# MKW36Z4 register map
Vendor: NXP Semiconductors; Series: Kinetis_W; File version: 1.6
CPU: CM0PLUS r0p0, little endian, no MPU, no FPU, VTOR, 2 interrupt priority bits
Registers are 16-bit, read-write, no defined reset value unless marked. A register's access mark holds for its fields unless they carry their own. Offsets are from the block's base; [hi:lo] are bit positions; {n}, {i} and the like mark numbered series; 'fields as' and 'values as' point back to an identical list.

## XCVR_TSM
Base 0x4005C2C0
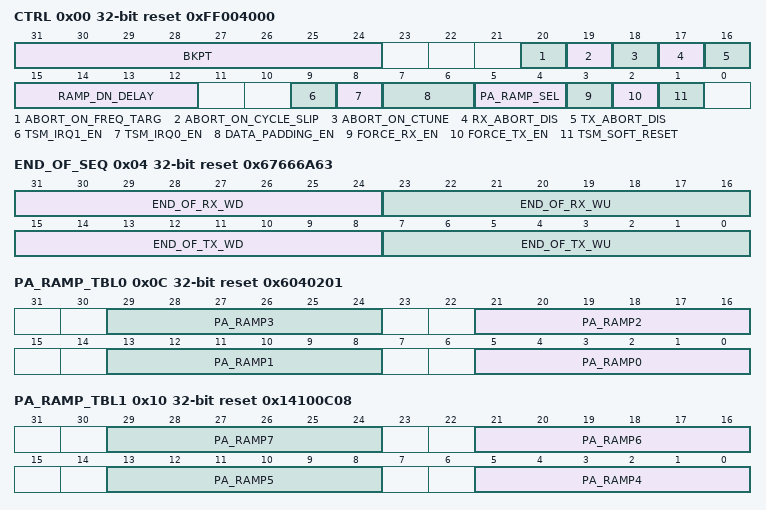
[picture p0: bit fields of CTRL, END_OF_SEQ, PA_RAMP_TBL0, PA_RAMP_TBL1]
0x00 CTRL 32-bit reset 0xFF004000 — TSM CONTROL
  [31:24] BKPT — TSM Breakpoint
  [20] ABORT_ON_FREQ_TARG — Abort On Frequency Target Lock Detect Failure
    0=don't allow TSM abort on Frequency Target Unlock Detect; 1=allow TSM abort on Frequency Target Unlock Detect
  [19] ABORT_ON_CYCLE_SLIP — Abort On Cycle Slip Lock Detect Failure
    0=don't allow TSM abort on Cycle Slip Unlock Detect; 1=allow TSM abort on Cycle Slip Unlock Detect
  [18] ABORT_ON_CTUNE — Abort On Coarse Tune Lock Detect Failure
    0=don't allow TSM abort on Coarse Tune Unlock Detect; 1=allow TSM abort on Coarse Tune Unlock Detect
  [17] RX_ABORT_DIS — Receive Abort Disable
  [16] TX_ABORT_DIS — Transmit Abort Disable
  [15:12] RAMP_DN_DELAY — PA Ramp Down Delay
  [9] TSM_IRQ1_EN — TSM_IRQ1 Enable/Disable bit
    0=TSM_IRQ1 is disabled; 1=TSM_IRQ1 is enabled
  [8] TSM_IRQ0_EN — TSM_IRQ0 Enable/Disable bit
    0=TSM_IRQ0 is disabled; 1=TSM_IRQ0 is enabled
  [7:6] DATA_PADDING_EN — Data Padding Enable
    0=Disable TX Data Padding; 1=Enable TX Data Padding
  [5:4] PA_RAMP_SEL — PA Ramp Selection
  [3] FORCE_RX_EN — Force Receive Enable
    0=TSM Idle; 1=TSM executes a RX sequence
  [2] FORCE_TX_EN — Force Transmit Enable
    0=TSM Idle; 1=TSM executes a TX sequence
  [1] TSM_SOFT_RESET
    0=TSM Soft Reset removed. Normal operation.; 1=TSM Soft Reset engaged. TSM forced to IDLE, and holds there until the bit is cleared.
0x04 END_OF_SEQ 32-bit reset 0x67666A63 — TSM END OF SEQUENCE
  [31:24] END_OF_RX_WD — End of RX Warmdown
  [23:16] END_OF_RX_WU — End of RX Warmup
  [15:8] END_OF_TX_WD — End of TX Warmdown
  [7:0] END_OF_TX_WU — End of TX Warmup
0x08 PA_POWER 32-bit reset 0x0
  [5:0] PA_POWER
0x0C PA_RAMP_TBL0 32-bit reset 0x6040201 — PA RAMP TABLE 0
  [8n+5:8n] PA_RAMP{n} (n=0..3)
0x10 PA_RAMP_TBL1 32-bit reset 0x14100C08 — PA RAMP TABLE 1
  [8n-27:8n-32] PA_RAMP{n} (n=4..7)
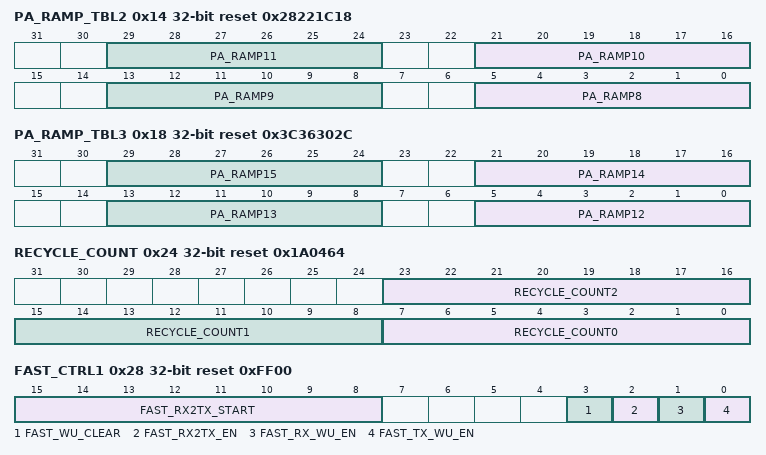
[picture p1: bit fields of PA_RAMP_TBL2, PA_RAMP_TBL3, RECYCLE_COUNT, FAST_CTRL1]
0x14 PA_RAMP_TBL2 32-bit reset 0x28221C18 — PA RAMP TABLE 2
  [8n-59:8n-64] PA_RAMP{n} (n=8..11)
0x18 PA_RAMP_TBL3 32-bit reset 0x3C36302C — PA RAMP TABLE 3
  [8n-91:8n-96] PA_RAMP{n} (n=12..15)
0x24 RECYCLE_COUNT 32-bit reset 0x1A0464 — TSM RECYCLE COUNT
  [23:16] RECYCLE_COUNT2 — TSM RX Recycle Count 2
  [15:8] RECYCLE_COUNT1 — TSM RX Recycle Count 1
  [7:0] RECYCLE_COUNT0 — TSM RX Recycle Count 0
0x28 FAST_CTRL1 32-bit reset 0xFF00 — TSM FAST WARMUP CONTROL 1
  [15:8] FAST_RX2TX_START — These bits currently have no functionality.
  [3] FAST_WU_CLEAR — Fast TSM Warmup Clear State
  [2] FAST_RX2TX_EN — Fast TSM RX-to-TX Transition Enable
  [1] FAST_RX_WU_EN — Fast TSM RX Warmup Enable
    0=Fast TSM RX Warmups are disabled; 1=Fast TSM RX Warmups are enabled, if the RF channel has not changed since the last RX warmup, and for BLE mode, the RF channel is not an advertising channel
  [0] FAST_TX_WU_EN — Fast TSM TX Warmup Enable
    0=Fast TSM TX Warmups are disabled; 1=Fast TSM TX Warmups are enabled, if the RF channel has not changed since the last TX warmup, and for BLE mode, the RF channel is not an advertising channel
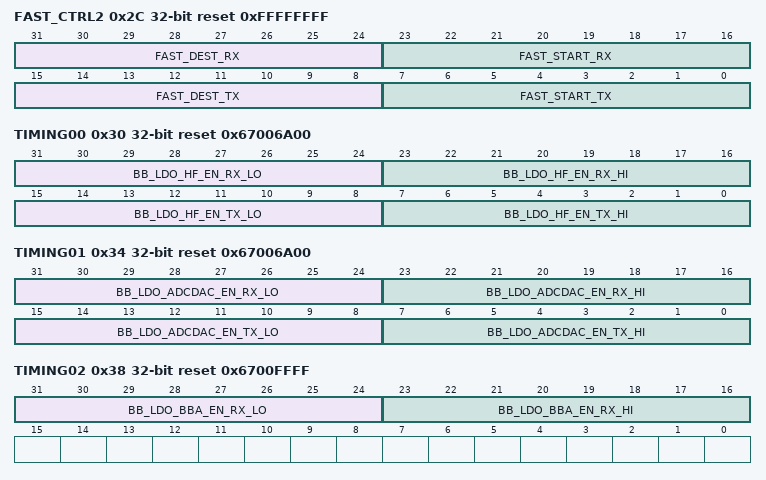
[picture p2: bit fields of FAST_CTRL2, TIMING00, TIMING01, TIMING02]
0x2C FAST_CTRL2 32-bit reset 0xFFFFFFFF — TSM FAST WARMUP CONTROL 2
  [31:24] FAST_DEST_RX — Fast TSM RX "Jump-to" Point
  [23:16] FAST_START_RX — Fast TSM RX "Jump-from" Point
  [15:8] FAST_DEST_TX — Fast TSM TX "Jump-to" Point
  [7:0] FAST_START_TX — Fast TSM TX "Jump-from" Point
0x30 TIMING00 32-bit reset 0x67006A00 — TSM_TIMING00
  [31:24] BB_LDO_HF_EN_RX_LO — De-assertion time setting for BB_LDO_HF_EN (RX)
  [23:16] BB_LDO_HF_EN_RX_HI — Assertion time setting for BB_LDO_HF_EN (RX)
  [15:8] BB_LDO_HF_EN_TX_LO — De-assertion time setting for BB_LDO_HF_EN (TX)
  [7:0] BB_LDO_HF_EN_TX_HI — Assertion time setting for BB_LDO_HF_EN (TX)
0x34 TIMING01 32-bit reset 0x67006A00 — TSM_TIMING01
  [31:24] BB_LDO_ADCDAC_EN_RX_LO — De-assertion time setting for BB_LDO_ADCDAC_EN (RX)
  [23:16] BB_LDO_ADCDAC_EN_RX_HI — Assertion time setting for BB_LDO_ADCDAC_EN (RX)
  [15:8] BB_LDO_ADCDAC_EN_TX_LO — De-assertion time setting for BB_LDO_ADCDAC_EN (TX)
  [7:0] BB_LDO_ADCDAC_EN_TX_HI — Assertion time setting for BB_LDO_ADCDAC_EN (TX)
0x38 TIMING02 32-bit reset 0x6700FFFF — TSM_TIMING02
  [31:24] BB_LDO_BBA_EN_RX_LO — De-assertion time setting for BB_LDO_BBA_EN (RX)
  [23:16] BB_LDO_BBA_EN_RX_HI — Assertion time setting for BB_LDO_BBA_EN (RX)
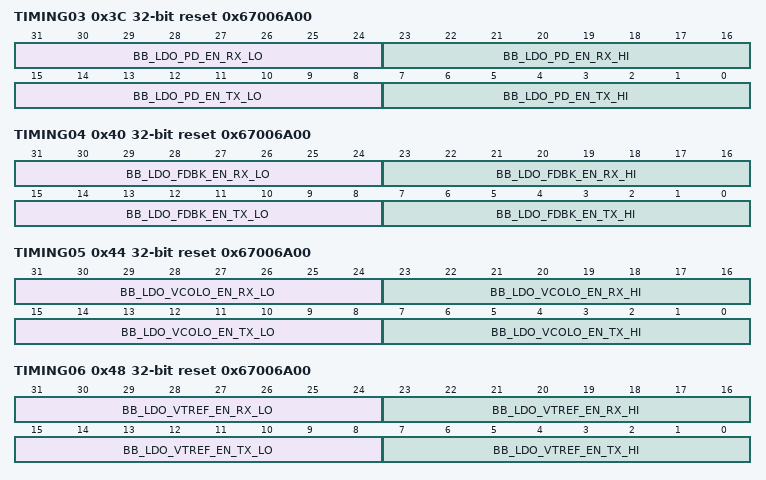
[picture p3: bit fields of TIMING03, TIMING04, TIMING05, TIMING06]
0x3C TIMING03 32-bit reset 0x67006A00 — TSM_TIMING03
  [31:24] BB_LDO_PD_EN_RX_LO — De-assertion time setting for BB_LDO_PD_EN (RX)
  [23:16] BB_LDO_PD_EN_RX_HI — Assertion time setting for BB_LDO_PD_EN (RX)
  [15:8] BB_LDO_PD_EN_TX_LO — De-assertion time setting for BB_LDO_PD_EN (TX)
  [7:0] BB_LDO_PD_EN_TX_HI — Assertion time setting for BB_LDO_PD_EN (TX)
0x40 TIMING04 32-bit reset 0x67006A00 — TSM_TIMING04
  [31:24] BB_LDO_FDBK_EN_RX_LO — De-assertion time setting for BB_LDO_FDBK_EN (RX)
  [23:16] BB_LDO_FDBK_EN_RX_HI — Assertion time setting for BB_LDO_FDBK_EN (RX)
  [15:8] BB_LDO_FDBK_EN_TX_LO — De-assertion time setting for BB_LDO_FDBK_EN (TX)
  [7:0] BB_LDO_FDBK_EN_TX_HI — Assertion time setting for BB_LDO_FDBK_EN (TX)
0x44 TIMING05 32-bit reset 0x67006A00 — TSM_TIMING05
  [31:24] BB_LDO_VCOLO_EN_RX_LO — De-assertion time setting for BB_LDO_VCOLO_EN (RX)
  [23:16] BB_LDO_VCOLO_EN_RX_HI — Assertion time setting for BB_LDO_VCOLO_EN (RX)
  [15:8] BB_LDO_VCOLO_EN_TX_LO — De-assertion time setting for BB_LDO_VCOLO_EN (TX)
  [7:0] BB_LDO_VCOLO_EN_TX_HI — Assertion time setting for BB_LDO_VCOLO_EN (TX)
0x48 TIMING06 32-bit reset 0x67006A00 — TSM_TIMING06
  [31:24] BB_LDO_VTREF_EN_RX_LO — De-assertion time setting for BB_LDO_VTREF_EN (RX)
  [23:16] BB_LDO_VTREF_EN_RX_HI — Assertion time setting for BB_LDO_VTREF_EN (RX)
  [15:8] BB_LDO_VTREF_EN_TX_LO — De-assertion time setting for BB_LDO_VTREF_EN (TX)
  [7:0] BB_LDO_VTREF_EN_TX_HI — Assertion time setting for BB_LDO_VTREF_EN (TX)
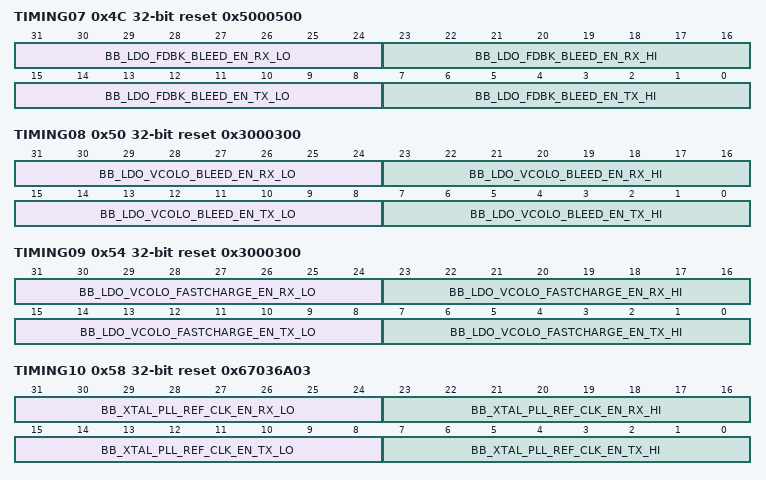
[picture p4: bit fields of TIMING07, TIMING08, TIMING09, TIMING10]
0x4C TIMING07 32-bit reset 0x5000500 — TSM_TIMING07
  [31:24] BB_LDO_FDBK_BLEED_EN_RX_LO — De-assertion time setting for BB_LDO_FDBK_BLEED_EN (RX)
  [23:16] BB_LDO_FDBK_BLEED_EN_RX_HI — Assertion time setting for BB_LDO_FDBK_BLEED_EN (RX)
  [15:8] BB_LDO_FDBK_BLEED_EN_TX_LO — De-assertion time setting for BB_LDO_FDBK_BLEED_EN (TX)
  [7:0] BB_LDO_FDBK_BLEED_EN_TX_HI — Assertion time setting for BB_LDO_FDBK_BLEED_EN (TX)
0x50 TIMING08 32-bit reset 0x3000300 — TSM_TIMING08
  [31:24] BB_LDO_VCOLO_BLEED_EN_RX_LO — De-assertion time setting for BB_LDO_VCOLO_BLEED_EN (RX)
  [23:16] BB_LDO_VCOLO_BLEED_EN_RX_HI — Assertion time setting for BB_LDO_VCOLO_BLEED_EN (RX)
  [15:8] BB_LDO_VCOLO_BLEED_EN_TX_LO — De-assertion time setting for BB_LDO_VCOLO_BLEED_EN (TX)
  [7:0] BB_LDO_VCOLO_BLEED_EN_TX_HI — Assertion time setting for BB_LDO_VCOLO_BLEED_EN (TX)
0x54 TIMING09 32-bit reset 0x3000300 — TSM_TIMING09
  [31:24] BB_LDO_VCOLO_FASTCHARGE_EN_RX_LO — De-assertion time setting for BB_LDO_VCOLO_FASTCHARGE_EN (RX)
  [23:16] BB_LDO_VCOLO_FASTCHARGE_EN_RX_HI — Assertion time setting for BB_LDO_VCOLO_FASTCHARGE_EN (RX)
  [15:8] BB_LDO_VCOLO_FASTCHARGE_EN_TX_LO — De-assertion time setting for BB_LDO_VCOLO_FASTCHARGE_EN (TX)
  [7:0] BB_LDO_VCOLO_FASTCHARGE_EN_TX_HI — Assertion time setting for BB_LDO_VCOLO_FASTCHARGE_EN (TX)
0x58 TIMING10 32-bit reset 0x67036A03 — TSM_TIMING10
  [31:24] BB_XTAL_PLL_REF_CLK_EN_RX_LO — De-assertion time setting for BB_XTAL_PLL_REF_CLK_EN (RX)
  [23:16] BB_XTAL_PLL_REF_CLK_EN_RX_HI — Assertion time setting for BB_XTAL_PLL_REF_CLK_EN (RX)
  [15:8] BB_XTAL_PLL_REF_CLK_EN_TX_LO — De-assertion time setting for BB_XTAL_PLL_REF_CLK_EN (TX)
  [7:0] BB_XTAL_PLL_REF_CLK_EN_TX_HI — Assertion time setting for BB_XTAL_PLL_REF_CLK_EN (TX)
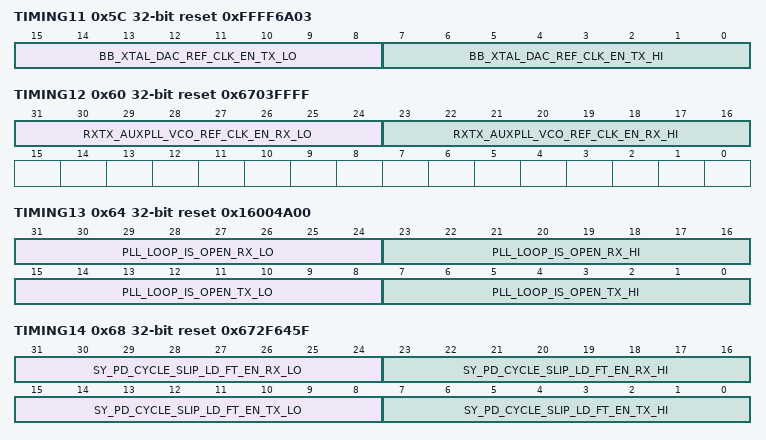
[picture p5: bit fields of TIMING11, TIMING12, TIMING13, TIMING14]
0x5C TIMING11 32-bit reset 0xFFFF6A03 — TSM_TIMING11
  [15:8] BB_XTAL_DAC_REF_CLK_EN_TX_LO — De-assertion time setting for BB_XTAL_DAC_REF_CLK_EN (TX)
  [7:0] BB_XTAL_DAC_REF_CLK_EN_TX_HI — Assertion time setting for BB_XTAL_DAC_REF_CLK_EN (TX)
0x60 TIMING12 32-bit reset 0x6703FFFF — TSM_TIMING12
  [31:24] RXTX_AUXPLL_VCO_REF_CLK_EN_RX_LO — De-assertion time setting for RXTX_AUXPLL_VCO_REF_CLK_EN (RX)
  [23:16] RXTX_AUXPLL_VCO_REF_CLK_EN_RX_HI — Assertion time setting for RXTX_AUXPLL_VCO_REF_CLK_EN (RX)
0x64 TIMING13 32-bit reset 0x16004A00 — TSM_TIMING13
  [31:24] PLL_LOOP_IS_OPEN_RX_LO — De-assertion time setting for PLL_LOOP_IS_OPEN (RX)
  [23:16] PLL_LOOP_IS_OPEN_RX_HI — Assertion time setting for PLL_LOOP_IS_OPEN (RX)
  [15:8] PLL_LOOP_IS_OPEN_TX_LO — De-assertion time setting for PLL_LOOP_IS_OPEN (TX)
  [7:0] PLL_LOOP_IS_OPEN_TX_HI — Assertion time setting for PLL_LOOP_IS_OPEN (TX)
0x68 TIMING14 32-bit reset 0x672F645F — TSM_TIMING14
  [31:24] SY_PD_CYCLE_SLIP_LD_FT_EN_RX_LO — De-assertion time setting for SY_PD_CYCLE_SLIP_LD_FT_EN (RX)
  [23:16] SY_PD_CYCLE_SLIP_LD_FT_EN_RX_HI — Assertion time setting for SY_PD_CYCLE_SLIP_LD_FT_EN (RX)
  [15:8] SY_PD_CYCLE_SLIP_LD_FT_EN_TX_LO — De-assertion time setting for SY_PD_CYCLE_SLIP_LD_FT_EN (TX)
  [7:0] SY_PD_CYCLE_SLIP_LD_FT_EN_TX_HI — Assertion time setting for SY_PD_CYCLE_SLIP_LD_FT_EN (TX)
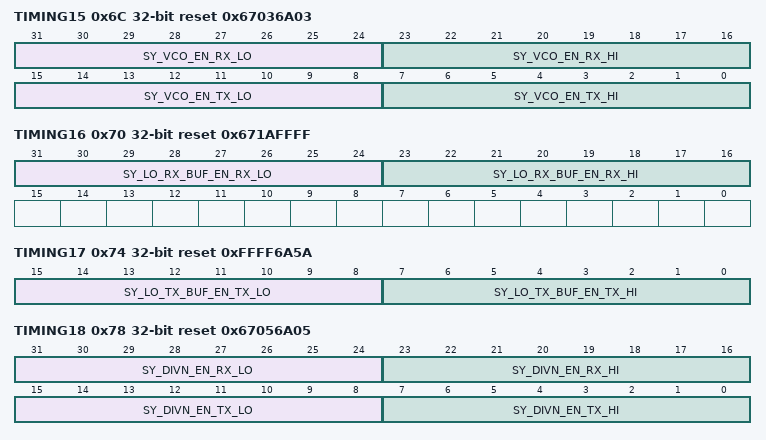
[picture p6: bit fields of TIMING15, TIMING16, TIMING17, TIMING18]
0x6C TIMING15 32-bit reset 0x67036A03 — TSM_TIMING15
  [31:24] SY_VCO_EN_RX_LO — De-assertion time setting for SY_VCO_EN (RX)
  [23:16] SY_VCO_EN_RX_HI — Assertion time setting for SY_VCO_EN (RX)
  [15:8] SY_VCO_EN_TX_LO — De-assertion time setting for SY_VCO_EN (TX)
  [7:0] SY_VCO_EN_TX_HI — Assertion time setting for SY_VCO_EN (TX)
0x70 TIMING16 32-bit reset 0x671AFFFF — TSM_TIMING16
  [31:24] SY_LO_RX_BUF_EN_RX_LO — De-assertion time setting for SY_LO_RX_BUF_EN (RX)
  [23:16] SY_LO_RX_BUF_EN_RX_HI — Assertion time setting for SY_LO_RX_BUF_EN (RX)
0x74 TIMING17 32-bit reset 0xFFFF6A5A — TSM_TIMING17
  [15:8] SY_LO_TX_BUF_EN_TX_LO — De-assertion time setting for SY_LO_TX_BUF_EN (TX)
  [7:0] SY_LO_TX_BUF_EN_TX_HI — Assertion time setting for SY_LO_TX_BUF_EN (TX)
0x78 TIMING18 32-bit reset 0x67056A05 — TSM_TIMING18
  [31:24] SY_DIVN_EN_RX_LO — De-assertion time setting for SY_DIVN_EN (RX)
  [23:16] SY_DIVN_EN_RX_HI — Assertion time setting for SY_DIVN_EN (RX)
  [15:8] SY_DIVN_EN_TX_LO — De-assertion time setting for SY_DIVN_EN (TX)
  [7:0] SY_DIVN_EN_TX_HI — Assertion time setting for SY_DIVN_EN (TX)
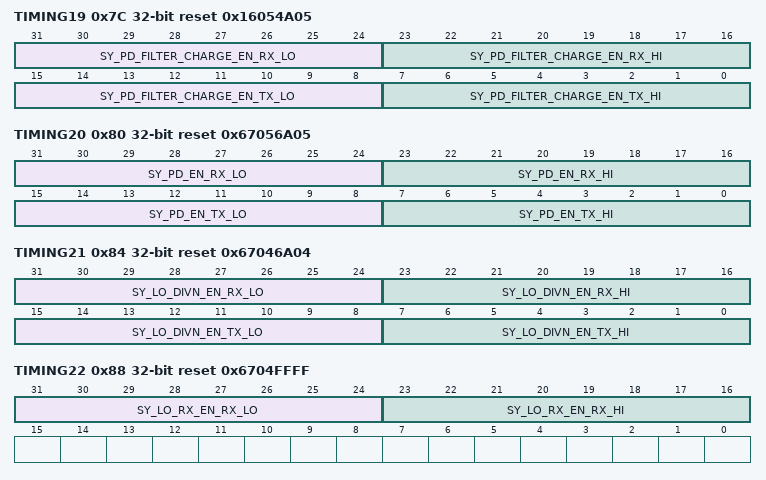
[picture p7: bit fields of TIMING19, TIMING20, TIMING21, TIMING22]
0x7C TIMING19 32-bit reset 0x16054A05 — TSM_TIMING19
  [31:24] SY_PD_FILTER_CHARGE_EN_RX_LO — De-assertion time setting for SY_PD_FILTER_CHARGE_EN (RX)
  [23:16] SY_PD_FILTER_CHARGE_EN_RX_HI — Assertion time setting for SY_PD_FILTER_CHARGE_EN (RX)
  [15:8] SY_PD_FILTER_CHARGE_EN_TX_LO — De-assertion time setting for SY_PD_FILTER_CHARGE_EN (TX)
  [7:0] SY_PD_FILTER_CHARGE_EN_TX_HI — Assertion time setting for SY_PD_FILTER_CHARGE_EN (TX)
0x80 TIMING20 32-bit reset 0x67056A05 — TSM_TIMING20
  [31:24] SY_PD_EN_RX_LO — De-assertion time setting for SY_PD_EN (RX)
  [23:16] SY_PD_EN_RX_HI — Assertion time setting for SY_PD_EN (RX)
  [15:8] SY_PD_EN_TX_LO — De-assertion time setting for SY_PD_EN (TX)
  [7:0] SY_PD_EN_TX_HI — Assertion time setting for SY_PD_EN (TX)
0x84 TIMING21 32-bit reset 0x67046A04 — TSM_TIMING21
  [31:24] SY_LO_DIVN_EN_RX_LO — De-assertion time setting for SY_LO_DIVN_EN (RX)
  [23:16] SY_LO_DIVN_EN_RX_HI — Assertion time setting for SY_LO_DIVN_EN (RX)
  [15:8] SY_LO_DIVN_EN_TX_LO — De-assertion time setting for SY_LO_DIVN_EN (TX)
  [7:0] SY_LO_DIVN_EN_TX_HI — Assertion time setting for SY_LO_DIVN_EN (TX)
0x88 TIMING22 32-bit reset 0x6704FFFF — TSM_TIMING22
  [31:24] SY_LO_RX_EN_RX_LO — De-assertion time setting for SY_LO_RX_EN (RX)
  [23:16] SY_LO_RX_EN_RX_HI — Assertion time setting for SY_LO_RX_EN (RX)
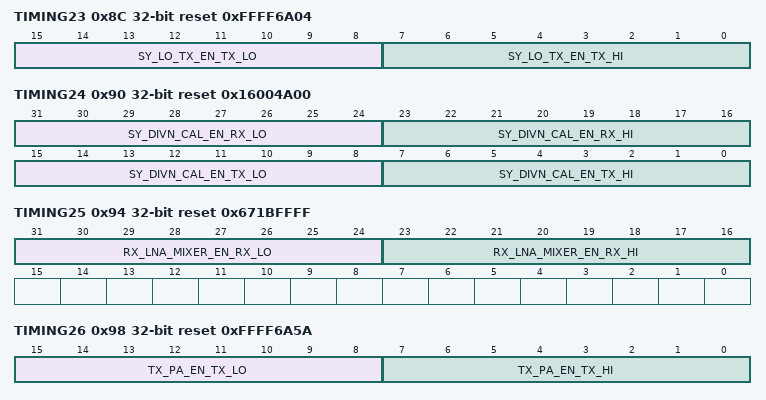
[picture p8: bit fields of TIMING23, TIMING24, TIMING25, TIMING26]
0x8C TIMING23 32-bit reset 0xFFFF6A04 — TSM_TIMING23
  [15:8] SY_LO_TX_EN_TX_LO — De-assertion time setting for SY_LO_TX_EN (TX)
  [7:0] SY_LO_TX_EN_TX_HI — Assertion time setting for SY_LO_TX_EN (TX)
0x90 TIMING24 32-bit reset 0x16004A00 — TSM_TIMING24
  [31:24] SY_DIVN_CAL_EN_RX_LO — De-assertion time setting for SY_DIVN_CAL_EN (RX)
  [23:16] SY_DIVN_CAL_EN_RX_HI — Assertion time setting for SY_DIVN_CAL_EN (RX)
  [15:8] SY_DIVN_CAL_EN_TX_LO — De-assertion time setting for SY_DIVN_CAL_EN (TX)
  [7:0] SY_DIVN_CAL_EN_TX_HI — Assertion time setting for SY_DIVN_CAL_EN (TX)
0x94 TIMING25 32-bit reset 0x671BFFFF — TSM_TIMING25
  [31:24] RX_LNA_MIXER_EN_RX_LO — De-assertion time setting for RX_LNA_MIXER_EN (RX)
  [23:16] RX_LNA_MIXER_EN_RX_HI — Assertion time setting for RX_LNA_MIXER_EN (RX)
0x98 TIMING26 32-bit reset 0xFFFF6A5A — TSM_TIMING26
  [15:8] TX_PA_EN_TX_LO — De-assertion time setting for TX_PA_EN (TX)
  [7:0] TX_PA_EN_TX_HI — Assertion time setting for TX_PA_EN (TX)
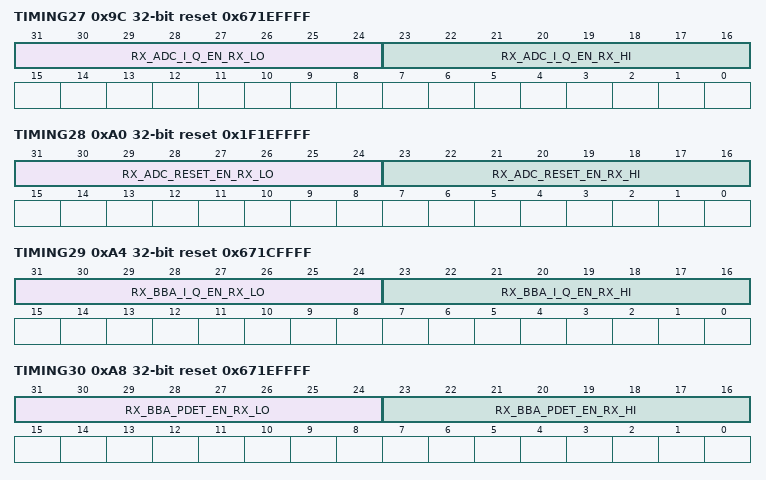
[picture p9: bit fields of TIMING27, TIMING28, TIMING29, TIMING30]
0x9C TIMING27 32-bit reset 0x671EFFFF — TSM_TIMING27
  [31:24] RX_ADC_I_Q_EN_RX_LO — De-assertion time setting for RX_ADC_I_Q_EN (RX)
  [23:16] RX_ADC_I_Q_EN_RX_HI — Assertion time setting for RX_ADC_I_Q_EN (RX)
0xA0 TIMING28 32-bit reset 0x1F1EFFFF — TSM_TIMING28
  [31:24] RX_ADC_RESET_EN_RX_LO — De-assertion time setting for RX_ADC_RESET_EN (RX)
  [23:16] RX_ADC_RESET_EN_RX_HI — Assertion time setting for RX_ADC_RESET_EN (RX)
0xA4 TIMING29 32-bit reset 0x671CFFFF — TSM_TIMING29
  [31:24] RX_BBA_I_Q_EN_RX_LO — De-assertion time setting for RX_BBA_I_Q_EN (RX)
  [23:16] RX_BBA_I_Q_EN_RX_HI — Assertion time setting for RX_BBA_I_Q_EN (RX)
0xA8 TIMING30 32-bit reset 0x671EFFFF — TSM_TIMING30
  [31:24] RX_BBA_PDET_EN_RX_LO — De-assertion time setting for RX_BBA_PDET_EN (RX)
  [23:16] RX_BBA_PDET_EN_RX_HI — Assertion time setting for RX_BBA_PDET_EN (RX)
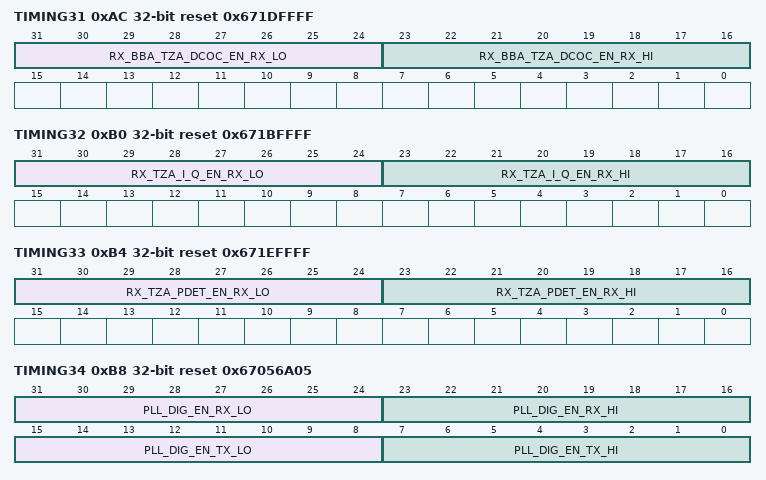
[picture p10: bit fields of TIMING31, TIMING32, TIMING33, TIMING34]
0xAC TIMING31 32-bit reset 0x671DFFFF — TSM_TIMING31
  [31:24] RX_BBA_TZA_DCOC_EN_RX_LO — De-assertion time setting for RX_BBA_TZA_DCOC_EN (RX)
  [23:16] RX_BBA_TZA_DCOC_EN_RX_HI — Assertion time setting for RX_BBA_TZA_DCOC_EN (RX)
0xB0 TIMING32 32-bit reset 0x671BFFFF — TSM_TIMING32
  [31:24] RX_TZA_I_Q_EN_RX_LO — De-assertion time setting for RX_TZA_I_Q_EN (RX)
  [23:16] RX_TZA_I_Q_EN_RX_HI — Assertion time setting for RX_TZA_I_Q_EN (RX)
0xB4 TIMING33 32-bit reset 0x671EFFFF — TSM_TIMING33
  [31:24] RX_TZA_PDET_EN_RX_LO — De-assertion time setting for RX_TZA_PDET_EN (RX)
  [23:16] RX_TZA_PDET_EN_RX_HI — Assertion time setting for RX_TZA_PDET_EN (RX)
0xB8 TIMING34 32-bit reset 0x67056A05 — TSM_TIMING34
  [31:24] PLL_DIG_EN_RX_LO — De-assertion time setting for PLL_DIG_EN (RX)
  [23:16] PLL_DIG_EN_RX_HI — Assertion time setting for PLL_DIG_EN (RX)
  [15:8] PLL_DIG_EN_TX_LO — De-assertion time setting for PLL_DIG_EN (TX)
  [7:0] PLL_DIG_EN_TX_HI — Assertion time setting for PLL_DIG_EN (TX)
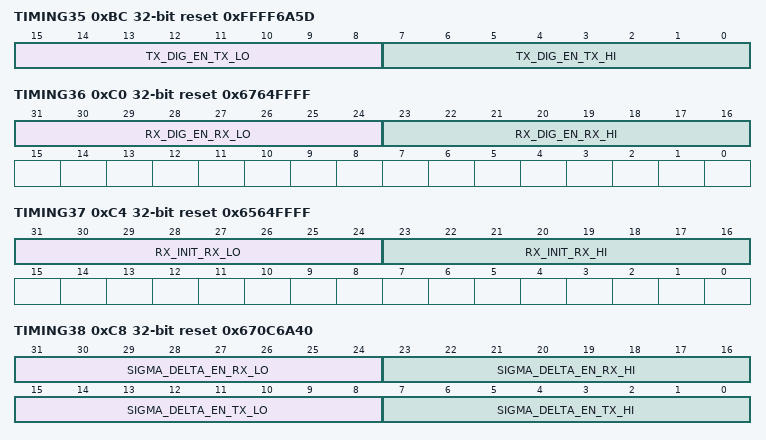
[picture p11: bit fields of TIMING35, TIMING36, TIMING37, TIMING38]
0xBC TIMING35 32-bit reset 0xFFFF6A5D — TSM_TIMING35
  [15:8] TX_DIG_EN_TX_LO — De-assertion time setting for TX_DIG_EN (TX)
  [7:0] TX_DIG_EN_TX_HI — Assertion time setting for TX_DIG_EN (TX)
0xC0 TIMING36 32-bit reset 0x6764FFFF — TSM_TIMING36
  [31:24] RX_DIG_EN_RX_LO — De-assertion time setting for RX_DIG_EN (RX)
  [23:16] RX_DIG_EN_RX_HI — Assertion time setting for RX_DIG_EN (RX)
0xC4 TIMING37 32-bit reset 0x6564FFFF — TSM_TIMING37
  [31:24] RX_INIT_RX_LO — De-assertion time setting for RX_INIT (RX)
  [23:16] RX_INIT_RX_HI — Assertion time setting for RX_INIT (RX)
0xC8 TIMING38 32-bit reset 0x670C6A40 — TSM_TIMING38
  [31:24] SIGMA_DELTA_EN_RX_LO — De-assertion time setting for SIGMA_DELTA_EN (RX)
  [23:16] SIGMA_DELTA_EN_RX_HI — Assertion time setting for SIGMA_DELTA_EN (RX)
  [15:8] SIGMA_DELTA_EN_TX_LO — De-assertion time setting for SIGMA_DELTA_EN (TX)
  [7:0] SIGMA_DELTA_EN_TX_HI — Assertion time setting for SIGMA_DELTA_EN (TX)
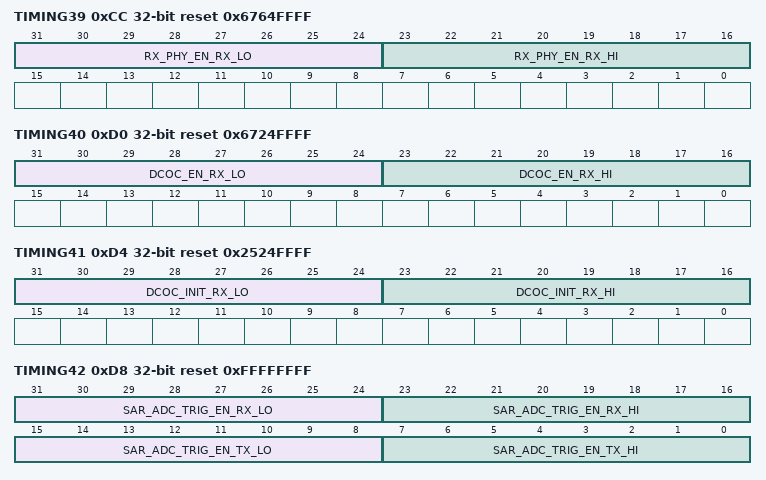
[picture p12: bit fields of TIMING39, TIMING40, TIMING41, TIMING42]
0xCC TIMING39 32-bit reset 0x6764FFFF — TSM_TIMING39
  [31:24] RX_PHY_EN_RX_LO — De-assertion time setting for RX_PHY_EN (RX)
  [23:16] RX_PHY_EN_RX_HI — Assertion time setting for RX_PHY_EN (RX)
0xD0 TIMING40 32-bit reset 0x6724FFFF — TSM_TIMING40
  [31:24] DCOC_EN_RX_LO — De-assertion time setting for DCOC_EN (RX)
  [23:16] DCOC_EN_RX_HI — Assertion time setting for DCOC_EN (RX)
0xD4 TIMING41 32-bit reset 0x2524FFFF — TSM_TIMING41
  [31:24] DCOC_INIT_RX_LO — De-assertion time setting for DCOC_INIT (RX)
  [23:16] DCOC_INIT_RX_HI — Assertion time setting for DCOC_INIT (RX)
0xD8 TIMING42 32-bit reset 0xFFFFFFFF — TSM_TIMING42
  [31:24] SAR_ADC_TRIG_EN_RX_LO — De-assertion time setting for SAR_ADC_TRIG_EN (RX)
  [23:16] SAR_ADC_TRIG_EN_RX_HI — Assertion time setting for SAR_ADC_TRIG_EN (RX)
  [15:8] SAR_ADC_TRIG_EN_TX_LO — De-assertion time setting for SAR_ADC_TRIG_EN (TX)
  [7:0] SAR_ADC_TRIG_EN_TX_HI — Assertion time setting for SAR_ADC_TRIG_EN (TX)
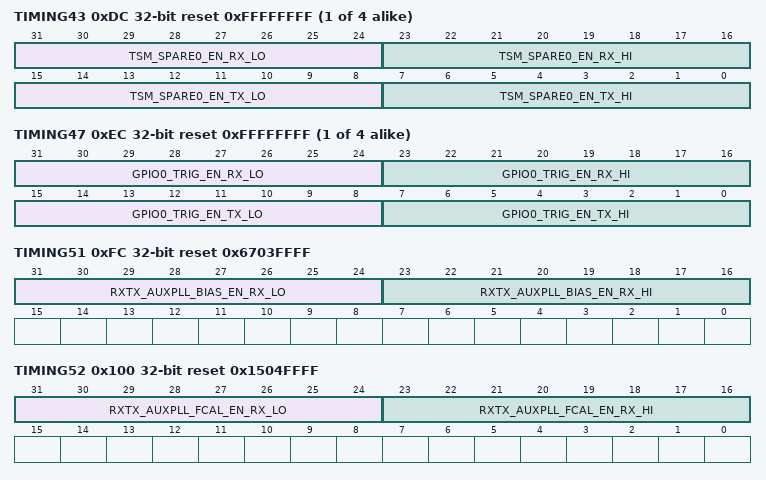
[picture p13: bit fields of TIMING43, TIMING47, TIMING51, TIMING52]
{0x30+4i} TIMING{i} 32-bit reset 0xFFFFFFFF (i=43..46) — TSM_TIMING{i}
  [31:24] TSM_SPARE{i-43}_EN_RX_LO — De-assertion time setting for TSM_SPARE{i-43}_EN (RX)
  [23:16] TSM_SPARE{i-43}_EN_RX_HI — Assertion time setting for TSM_SPARE{i-43}_EN (RX)
  [15:8] TSM_SPARE{i-43}_EN_TX_LO — De-assertion time setting for TSM_SPARE{i-43}_EN (TX)
  [7:0] TSM_SPARE{i-43}_EN_TX_HI — Assertion time setting for TSM_SPARE{i-43}_EN (TX)
{0x30+4i} TIMING{i} 32-bit reset 0xFFFFFFFF (i=47..50) — TSM_TIMING{i}
  [31:24] GPIO{i-47}_TRIG_EN_RX_LO — De-assertion time setting for GPIO{i-47}_TRIG_EN (RX)
  [23:16] GPIO{i-47}_TRIG_EN_RX_HI — Assertion time setting for GPIO{i-47}_TRIG_EN (RX)
  [15:8] GPIO{i-47}_TRIG_EN_TX_LO — De-assertion time setting for GPIO{i-47}_TRIG_EN (TX)
  [7:0] GPIO{i-47}_TRIG_EN_TX_HI — Assertion time setting for GPIO{i-47}_TRIG_EN (TX)
0xFC TIMING51 32-bit reset 0x6703FFFF — TSM_TIMING51
  [31:24] RXTX_AUXPLL_BIAS_EN_RX_LO — De-assertion time setting for RXTX_AUXPLL_BIAS_EN (RX)
  [23:16] RXTX_AUXPLL_BIAS_EN_RX_HI — Assertion time setting for RXTX_AUXPLL_BIAS_EN (RX)
0x100 TIMING52 32-bit reset 0x1504FFFF — TSM_TIMING52
  [31:24] RXTX_AUXPLL_FCAL_EN_RX_LO — De-assertion time setting for RXTX_AUXPLL_FCAL_EN (RX)
  [23:16] RXTX_AUXPLL_FCAL_EN_RX_HI — Assertion time setting for RXTX_AUXPLL_FCAL_EN (RX)
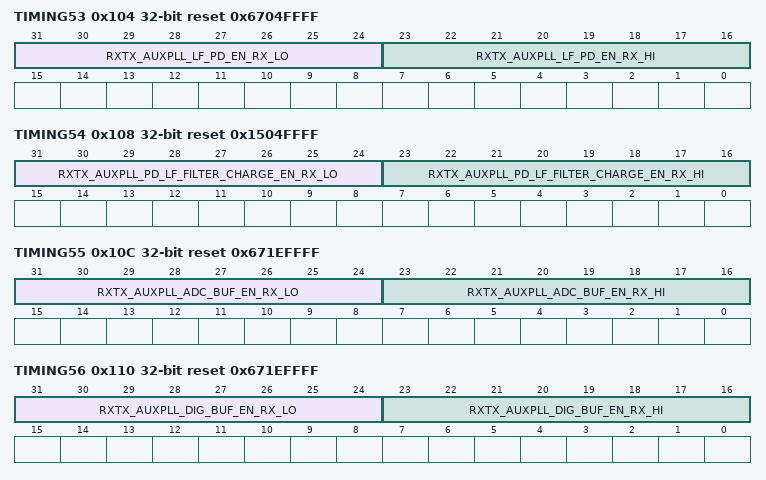
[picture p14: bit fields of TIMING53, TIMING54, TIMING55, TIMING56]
0x104 TIMING53 32-bit reset 0x6704FFFF — TSM_TIMING53
  [31:24] RXTX_AUXPLL_LF_PD_EN_RX_LO — De-assertion time setting for RXTX_AUXPLL_LF_PD_EN (RX)
  [23:16] RXTX_AUXPLL_LF_PD_EN_RX_HI — Assertion time setting for RXTX_AUXPLL_LF_PD_EN (RX)
0x108 TIMING54 32-bit reset 0x1504FFFF — TSM_TIMING54
  [31:24] RXTX_AUXPLL_PD_LF_FILTER_CHARGE_EN_RX_LO — De-assertion time setting for RXTX_AUXPLL_PD_LF_FILTER_CHARGE_EN (RX)
  [23:16] RXTX_AUXPLL_PD_LF_FILTER_CHARGE_EN_RX_HI — Assertion time setting for RXTX_AUXPLL_PD_LF_FILTER_CHARGE_EN (RX)
0x10C TIMING55 32-bit reset 0x671EFFFF — TSM_TIMING55
  [31:24] RXTX_AUXPLL_ADC_BUF_EN_RX_LO — De-assertion time setting for RXTX_AUXPLL_ADC_BUF_EN (RX)
  [23:16] RXTX_AUXPLL_ADC_BUF_EN_RX_HI — Assertion time setting for RXTX_AUXPLL_ADC_BUF_EN (RX)
0x110 TIMING56 32-bit reset 0x671EFFFF — TSM_TIMING56
  [31:24] RXTX_AUXPLL_DIG_BUF_EN_RX_LO — De-assertion time setting for RXTX_AUXPLL_DIG_BUF_EN (RX)
  [23:16] RXTX_AUXPLL_DIG_BUF_EN_RX_HI — Assertion time setting for RXTX_AUXPLL_DIG_BUF_EN (RX)
0x114 TIMING57 32-bit reset 0x1A03FFFF — TSM_TIMING57
  [31:24] RXTX_RCCAL_EN_RX_LO — De-assertion time setting for RXTX_RCCAL_EN (RX)
  [23:16] RXTX_RCCAL_EN_RX_HI — Assertion time setting for RXTX_RCCAL_EN (RX)
0x118 TIMING58 32-bit reset 0xFFFF6A03 — TSM_TIMING58
  [15:8] TX_HPM_DAC_EN_TX_LO — De-assertion time setting for TX_HPM_DAC_EN (TX)
  [7:0] TX_HPM_DAC_EN_TX_HI — Assertion time setting for TX_HPM_DAC_EN (TX)
0x11C OVRD0 32-bit reset 0x0 — TSM OVERRIDE REGISTER 0
  [31] SY_VCO_EN_OVRD — Override value for SY_VCO_EN
  [30] SY_VCO_EN_OVRD_EN — Override control for SY_VCO_EN
    0=Normal operation; 1=Use the state of SY_VCO_EN_OVRD to override the signal "sy_vco_en"
  [29] SY_PD_CYCLE_SLIP_LD_EN_OVRD — Override value for SY_PD_CYCLE_SLIP_LD_EN
  [28] SY_PD_CYCLE_SLIP_LD_EN_OVRD_EN — Override control for SY_PD_CYCLE_SLIP_LD_EN
    0=Normal operation; 1=Use the state of SY_PD_CYCLE_SLIP_LD_EN_OVRD to override the signal "sy_pd_cycle_slip_ld_en"
  [27] PLL_LOOP_IS_OPEN_OVRD — Override value for PLL_LOOP_IS_OPEN
  [26] PLL_LOOP_IS_OPEN_OVRD_EN — Override control for PLL_LOOP_IS_OPEN
    0=Normal operation; 1=Use the state of PLL_LOOP_IS_OPEN_OVRD to override the signal "pll_loop_is_open"
  [25] BB_XTAL_AUXPLL_REF_CLK_EN_OVRD — Override value for BB_XTAL_AUXPLL_REF_CLK_EN
  [24] BB_XTAL_AUXPLL_REF_CLK_EN_OVRD_EN — Override control for BB_XTAL_AUXPLL_REF_CLK_EN
    0=Normal operation; 1=Use the state of BB_XTAL_AUXPLL_REF_CLK_EN_OVRD to override the signal "bb_xtal_auxpll_ref_clk_en"
  [23] BB_XTAL_DAC_REF_CLK_EN_OVRD — Override value for BB_XTAL_DAC_REF_CLK_EN
  [22] BB_XTAL_DAC_REF_CLK_EN_OVRD_EN — Override control for BB_XTAL_DAC_REF_CLK_EN
    0=Normal operation; 1=Use the state of BB_XTAL_DAC_REF_CLK_EN_OVRD to override the signal "bb_xtal_dac_ref_clk_en"
  [21] BB_XTAL_PLL_REF_CLK_EN_OVRD — Override value for BB_XTAL_PLL_REF_CLK_EN
  [20] BB_XTAL_PLL_REF_CLK_EN_OVRD_EN — Override control for BB_XTAL_PLL_REF_CLK_EN
    0=Normal operation; 1=Use the state of BB_XTAL_PLL_REF_CLK_EN_OVRD to override the signal "bb_xtal_pll_ref_clk_en"
  [19] BB_LDO_VCOLO_FASTCHARGE_EN_OVRD — Override value for BB_LDO_VCOLO_FASTCHARGE_EN
  [18] BB_LDO_VCOLO_FASTCHARGE_EN_OVRD_EN — Override control for BB_LDO_VCOLO_FASTCHARGE_EN
    0=Normal operation; 1=Use the state of BB_LDO_VCOLO_FASTCHARGE_EN_OVRD to override the signal "bb_ldo_vcolo_fastcharge_en"
  [17] BB_LDO_VCOLO_BLEED_EN_OVRD — Override value for BB_LDO_VCOLO_BLEED_EN
  [16] BB_LDO_VCOLO_BLEED_EN_OVRD_EN — Override control for BB_LDO_VCOLO_BLEED_EN
    0=Normal operation; 1=Use the state of BB_LDO_VCOLO_BLEED_EN_OVRD to override the signal "bb_ldo_vcolo_bleed_en"
  [15] BB_LDO_FDBK_BLEED_EN_OVRD — Override value for BB_LDO_FDBK_BLEED_EN
  [14] BB_LDO_FDBK_BLEED_EN_OVRD_EN — Override control for BB_LDO_FDBK_BLEED_EN
    0=Normal operation; 1=Use the state of BB_LDO_FDBK_BLEED_EN_OVRD to override the signal "bb_ldo_fdbk_bleed_en"
  [13] BB_LDO_VTREF_EN_OVRD — Override value for BB_LDO_VTREF_EN
  [12] BB_LDO_VTREF_EN_OVRD_EN — Override control for BB_LDO_VTREF_EN
    0=Normal operation; 1=Use the state of BB_LDO_VTREF_EN_OVRD to override the signal "bb_ldo_vtref_en"
  [11] BB_LDO_VCOLO_EN_OVRD — Override value for BB_LDO_VCOLO_EN
  [10] BB_LDO_VCOLO_EN_OVRD_EN — Override control for BB_LDO_VCOLO_EN
    0=Normal operation; 1=Use the state of BB_LDO_VCOLO_EN_OVRD to override the signal "bb_ldo_vcolo_en"
  [9] BB_LDO_FDBK_EN_OVRD — Override value for BB_LDO_FDBK_EN
  [8] BB_LDO_FDBK_EN_OVRD_EN — Override control for BB_LDO_FDBK_EN
    0=Normal operation; 1=Use the state of BB_LDO_FDBK_EN_OVRD to override the signal "bb_ldo_fdbk_en"
  [7] BB_LDO_PD_EN_OVRD — Override value for BB_LDO_PD_EN
  [6] BB_LDO_PD_EN_OVRD_EN — Override control for BB_LDO_PD_EN
    0=Normal operation; 1=Use the state of BB_LDO_PD_EN_OVRD to override the signal "bb_ldo_pd_en"
  [5] BB_LDO_BBA_EN_OVRD — Override value for BB_LDO_BBA_EN
  [4] BB_LDO_BBA_EN_OVRD_EN — Override control for BB_LDO_BBA_EN
    0=Normal operation; 1=Use the state of BB_LDO_BBA_EN_OVRD to override the signal "bb_ldo_bba_en"
  [3] BB_LDO_ADCDAC_EN_OVRD — Override value for BB_LDO_ADCDAC_EN
  [2] BB_LDO_ADCDAC_EN_OVRD_EN — Override control for BB_LDO_ADCDAC_EN
    0=Normal operation; 1=Use the state of BB_LDO_ADCDAC_EN_OVRD to override the signal "bb_ldo_adcdac_en"
  [1] BB_LDO_HF_EN_OVRD — Override value for BB_LDO_HF_EN
  [0] BB_LDO_HF_EN_OVRD_EN — Override control for BB_LDO_HF_EN
    0=Normal operation; 1=Use the state of BB_LDO_HF_EN_OVRD to override the signal "bb_ldo_hf_en"
0x120 OVRD1 32-bit reset 0x0 — TSM OVERRIDE REGISTER 1
  [31] RX_BBA_Q_EN_OVRD — Override value for RX_BBA_Q_EN
  [30] RX_BBA_Q_EN_OVRD_EN — Override control for RX_BBA_Q_EN
    0=Normal operation; 1=Use the state of RX_BBA_Q_EN_OVRD to override the signal "rx_bba_q_en"
  [29] RX_BBA_I_EN_OVRD — Override value for RX_BBA_I_EN
  [28] RX_BBA_I_EN_OVRD_EN — Override control for RX_BBA_I_EN
    0=Normal operation; 1=Use the state of RX_BBA_I_EN_OVRD to override the signal "rx_bba_i_en"
  [27] RX_ADC_RESET_EN_OVRD — Override value for RX_ADC_RESET_EN
  [26] RX_ADC_RESET_EN_OVRD_EN — Override control for RX_ADC_RESET_EN
    0=Normal operation; 1=Use the state of RX_ADC_RESET_EN_OVRD to override the signal "rx_adc_reset_en"
  [25] RX_ADC_Q_EN_OVRD — Override value for RX_ADC_Q_EN
  [24] RX_ADC_Q_EN_OVRD_EN — Override control for RX_ADC_Q_EN
    0=Normal operation; 1=Use the state of RX_ADC_Q_EN_OVRD to override the signal "rx_adc_q_en"
  [23] RX_ADC_I_EN_OVRD — Override value for RX_ADC_I_EN
  [22] RX_ADC_I_EN_OVRD_EN — Override control for RX_ADC_I_EN
    0=Normal operation; 1=Use the state of RX_ADC_I_EN_OVRD to override the signal "rx_adc_i_en"
  [21] TX_PA_EN_OVRD — Override value for TX_PA_EN
  [20] TX_PA_EN_OVRD_EN — Override control for TX_PA_EN
    0=Normal operation; 1=Use the state of TX_PA_EN_OVRD to override the signal "tx_pa_en"
  [19] RX_MIXER_EN_OVRD — Override value for RX_MIXER_EN
  [18] RX_MIXER_EN_OVRD_EN — Override control for RX_MIXER_EN
    0=Normal operation; 1=Use the state of RX_MIXER_EN_OVRD to override the signal "rx_mixer_en"
  [17] SY_DIVN_CAL_EN_OVRD — Override value for SY_DIVN_CAL_EN
  [16] SY_DIVN_CAL_EN_OVRD_EN — Override control for SY_DIVN_CAL_EN
    0=Normal operation; 1=Use the state of SY_DIVN_CAL_EN_OVRD to override the signal "sy_divn_cal_en"
  [15] SY_LO_TX_EN_OVRD — Override value for SY_LO_TX_EN
  [14] SY_LO_TX_EN_OVRD_EN — Override control for SY_LO_TX_EN
    0=Normal operation; 1=Use the state of SY_LO_TX_EN_OVRD to override the signal "sy_lo_tx_en"
  [13] SY_LO_RX_EN_OVRD — Override value for SY_LO_RX_EN
  [12] SY_LO_RX_EN_OVRD_EN — Override control for SY_LO_RX_EN
    0=Normal operation; 1=Use the state of SY_LO_RX_EN_OVRD to override the signal "sy_lo_rx_en"
  [11] SY_LO_DIVN_EN_OVRD — Override value for SY_LO_DIVN_EN
  [10] SY_LO_DIVN_EN_OVRD_EN — Override control for SY_LO_DIVN_EN
    0=Normal operation; 1=Use the state of SY_LO_DIVN_EN_OVRD to override the signal "sy_lo_divn_en"
  [9] SY_PD_EN_OVRD — Override value for SY_PD_EN
  [8] SY_PD_EN_OVRD_EN — Override control for SY_PD_EN
    0=Normal operation; 1=Use the state of SY_PD_EN_OVRD to override the signal "sy_pd_en"
  [7] SY_PD_FILTER_CHARGE_EN_OVRD — Override value for SY_PD_FILTER_CHARGE_EN
  [6] SY_PD_FILTER_CHARGE_EN_OVRD_EN — Override control for SY_PD_FILTER_CHARGE_EN
    0=Normal operation; 1=Use the state of SY_PD_FILTER_CHARGE_EN_OVRD to override the signal "sy_pd_filter_charge_en"
  [5] SY_DIVN_EN_OVRD — Override value for SY_DIVN_EN
  [4] SY_DIVN_EN_OVRD_EN — Override control for SY_DIVN_EN
    0=Normal operation; 1=Use the state of SY_DIVN_EN_OVRD to override the signal "sy_divn_en"
  [3] SY_LO_TX_BUF_EN_OVRD — Override value for SY_LO_TX_BUF_EN
  [2] SY_LO_TX_BUF_EN_OVRD_EN — Override control for SY_LO_TX_BUF_EN
    0=Normal operation; 1=Use the state of SY_LO_TX_BUF_EN_OVRD to override the signal "sy_lo_tx_buf_en"
  [1] SY_LO_RX_BUF_EN_OVRD — Override value for SY_LO_RX_BUF_EN
  [0] SY_LO_RX_BUF_EN_OVRD_EN — Override control for SY_LO_RX_BUF_EN
    0=Normal operation; 1=Use the state of SY_LO_RX_BUF_EN_OVRD to override the signal "sy_lo_rx_buf_en"
0x124 OVRD2 32-bit reset 0x0 — TSM OVERRIDE REGISTER 2
  [31] FREQ_TARG_LD_EN_OVRD — Override value for FREQ_TARG_LD_EN
  [30] FREQ_TARG_LD_EN_OVRD_EN — Override control for FREQ_TARG_LD_EN
    0=Normal operation; 1=Use the state of FREQ_TARG_LD_EN_OVRD to override the signal "freq_targ_ld_en"
  [29] DCOC_INIT_OVRD — Override value for DCOC_INIT
  [28] DCOC_INIT_OVRD_EN — Override control for DCOC_INIT
    0=Normal operation; 1=Use the state of DCOC_INIT_OVRD to override the signal "dcoc_init"
  [27] DCOC_EN_OVRD — Override value for DCOC_EN
  [26] DCOC_EN_OVRD_EN — Override control for DCOC_EN
    0=Normal operation; 1=Use the state of DCOC_EN_OVRD to override the signal "dcoc_en"
  [25] RX_PHY_EN_OVRD — Override value for RX_PHY_EN
  [24] RX_PHY_EN_OVRD_EN — Override control for RX_PHY_EN
    0=Normal operation; 1=Use the state of RX_PHY_EN_OVRD to override the signal "rx_phy_en"
  [23] SIGMA_DELTA_EN_OVRD — Override value for SIGMA_DELTA_EN
  [22] SIGMA_DELTA_EN_OVRD_EN — Override control for SIGMA_DELTA_EN
    0=Normal operation; 1=Use the state of SIGMA_DELTA_EN_OVRD to override the signal "sigma_delta_en"
  [21] RX_INIT_OVRD — Override value for RX_INIT
  [20] RX_INIT_OVRD_EN — Override control for RX_INIT
    0=Normal operation; 1=Use the state of RX_INIT_OVRD to override the signal "rx_init"
  [19] RX_DIG_EN_OVRD — Override value for RX_DIG_EN
  [18] RX_DIG_EN_OVRD_EN — Override control for RX_DIG_EN
    0=Normal operation; 1=Use the state of RX_DIG_EN_OVRD to override the signal "rx_dig_en"
  [17] TX_DIG_EN_OVRD — Override value for TX_DIG_EN
  [16] TX_DIG_EN_OVRD_EN — Override control for TX_DIG_EN
    0=Normal operation; 1=Use the state of TX_DIG_EN_OVRD to override the signal "tx_dig_en"
  [15] PLL_DIG_EN_OVRD — Override value for PLL_DIG_EN
  [14] PLL_DIG_EN_OVRD_EN — Override control for PLL_DIG_EN
    0=Normal operation; 1=Use the state of PLL_DIG_EN_OVRD to override the signal "pll_dig_en"
  [13] RX_TZA_DCOC_EN_OVRD — Override control for RX_TZA_DCOC_EN
    0=Normal operation; 1=Use the state of RX_TZA_DCOC_EN_OVRD to override the signal "rx_tza_dcoc_en"
  [12] RX_TZA_DCOC_EN_OVRD_EN — Override control for RX_TZA_DCOC_EN
    values as RX_TZA_DCOC_EN_OVRD
  [11] RX_TZA_PDET_EN_OVRD — Override value for RX_TZA_PDET_EN
  [10] RX_TZA_PDET_EN_OVRD_EN — Override control for RX_TZA_PDET_EN
    0=Normal operation; 1=Use the state of RX_TZA_PDET_EN_OVRD to override the signal "rx_tza_pdet_en"
  [9] RX_TZA_Q_EN_OVRD — Override value for RX_TZA_Q_EN
  [8] RX_TZA_Q_EN_OVRD_EN — Override control for RX_TZA_Q_EN
    0=Normal operation; 1=Use the state of RX_TZA_Q_EN_OVRD to override the signal "rx_tza_q_en"
  [7] RX_TZA_I_EN_OVRD — Override value for RX_TZA_I_EN
  [6] RX_TZA_I_EN_OVRD_EN — Override control for RX_TZA_I_EN
    0=Normal operation; 1=Use the state of RX_TZA_I_EN_OVRD to override the signal "rx_tza_i_en"
  [5] RX_LNA_EN_OVRD — Override value for RX_LNA_EN
  [4] RX_LNA_EN_OVRD_EN — Override control for RX_LNA_EN
    0=Normal operation; 1=Use the state of RX_LNA_EN_OVRD to override the signal "rx_lna_en"
  [3] RX_BBA_DCOC_EN_OVRD — Override value for RX_BBA_DCOC_EN
  [2] RX_BBA_DCOC_EN_OVRD_EN — Override control for RX_BBA_DCOC_EN
    0=Normal operation; 1=Use the state of RX_BBA_DCOC_EN_OVRD to override the signal "rx_bba_dcoc_en"
  [1] RX_BBA_PDET_EN_OVRD — Override value for RX_BBA_PDET_EN
  [0] RX_BBA_PDET_EN_OVRD_EN — Override control for RX_BBA_PDET_EN
    0=Normal operation; 1=Use the state of RX_BBA_PDET_EN_OVRD to override the signal "rx_bba_pdet_en"
0x128 OVRD3 32-bit reset 0x0 — TSM OVERRIDE REGISTER 3
  [31] RX_MODE_OVRD — Override value for RX_MODE
  [30] RX_MODE_OVRD_EN — Override control for RX_MODE
    0=Normal operation; 1=Use the state of RX_MODE_OVRD to override the signal "rx_mode"
  [29] TX_MODE_OVRD — Override value for TX_MODE
  [28] TX_MODE_OVRD_EN — Override control for TX_MODE
    0=Normal operation; 1=Use the state of TX_MODE_OVRD to override the signal "tx_mode"
  [27] TX_HPM_DAC_EN_OVRD — Override value for TX_HPM_DAC_EN
  [26] TX_HPM_DAC_EN_OVRD_EN — Override control for TX_HPM_DAC_EN
    0=Normal operation; 1=Use the state of TX_HPM_DAC_EN_OVRD to override the signal "tx_hpm_dac_en"
  [25] RXTX_RCCAL_EN_OVRD — Override value for RXTX_RCCAL_EN
  [24] RXTX_RCCAL_EN_OVRD_EN — Override control for RXTX_RCCAL_EN
    0=Normal operation; 1=Use the state of RXTX_RCCAL_EN_OVRD to override the signal "rxtx_rccal_en"
  [23] RXTX_AUXPLL_DIG_BUF_EN_OVRD — Override value for RXTX_AUXPLL_DIG_BUF_EN
  [22] RXTX_AUXPLL_DIG_BUF_EN_OVRD_EN — Override control for RXTX_AUXPLL_DIG_BUF_EN
    0=Normal operation; 1=Use the state of RXTX_AUXPLL_DIG_BUF_EN_OVRD to override the signal "rxtx_auxpll_dig_buf_en"
  [21] RXTX_AUXPLL_ADC_BUF_EN_OVRD — Override value for RXTX_AUXPLL_ADC_BUF_EN
  [20] RXTX_AUXPLL_ADC_BUF_EN_OVRD_EN — Override control for RXTX_AUXPLL_ADC_BUF_EN
    0=Normal operation; 1=Use the state of RXTX_AUXPLL_ADC_BUF_EN_OVRD to override the signal "rxtx_auxpll_adc_buf_en"
  [19] RXTX_AUXPLL_PD_LF_FILTER_CHARGE_EN_OVRD — Override value for RXTX_AUXPLL_PD_LF_FILTER_CHARGE_EN
  [18] RXTX_AUXPLL_PD_LF_FILTER_CHARGE_EN_OVRD_EN — Override control for RXTX_AUXPLL_PD_LF_FILTER_CHARGE_EN
    0=Normal operation; 1=Use the state of RXTX_AUXPLL_PD_LF_FILTER_CHARGE_EN_OVRD to override the signal "rxtx_auxpll_pd_lf_filter_charge_en"
  [17] RXTX_AUXPLL_PD_EN_OVRD — Override value for RXTX_AUXPLL_PD_EN
  [16] RXTX_AUXPLL_PD_EN_OVRD_EN — Override control for RXTX_AUXPLL_PD_EN
    0=Normal operation; 1=Use the state of RXTX_AUXPLL_PD_EN_OVRD to override the signal "rxtx_auxpll_pd_en"
  [15] RXTX_AUXPLL_LF_EN_OVRD — Override value for RXTX_AUXPLL_LF_EN
  [14] RXTX_AUXPLL_LF_EN_OVRD_EN — Override control for RXTX_AUXPLL_LF_EN
    0=Normal operation; 1=Use the state of RXTX_AUXPLL_LF_EN_OVRD to override the signal "rxtx_auxpll_lf_en"
  [13] RXTX_AUXPLL_FCAL_EN_OVRD — Override value for RXTX_AUXPLL_FCAL_EN
  [12] RXTX_AUXPLL_FCAL_EN_OVRD_EN — Override control for RXTX_AUXPLL_FCAL_EN
    0=Normal operation; 1=Use the state of RXTX_AUXPLL_FCAL_EN_OVRD to override the signal "rxtx_auxpll_fcal_en"
  [11] RXTX_AUXPLL_VCO_EN_OVRD — Override value for RXTX_AUXPLL_VCO_EN
  [10] RXTX_AUXPLL_VCO_EN_OVRD_EN — Override control for RXTX_AUXPLL_VCO_EN
    0=Normal operation; 1=Use the state of RXTX_AUXPLL_VCO_EN_OVRD to override the signal "rxtx_auxpll_vco_en"
  [9] RXTX_AUXPLL_BIAS_EN_OVRD — Override value for RXTX_AUXPLL_BIAS_EN
  [8] RXTX_AUXPLL_BIAS_EN_OVRD_EN — Override control for RXTX_AUXPLL_BIAS_EN
    0=Normal operation; 1=Use the state of RXTX_AUXPLL_BIAS_EN_OVRD to override the signal "rxtx_auxpll_bias_en"
  [2n+1] TSM_SPARE{n}_EN_OVRD (n=0..3) — Override value for TSM_SPARE{n}_EN
  [2n] TSM_SPARE{n}_EN_OVRD_EN (n=0..3) — Override control for TSM_SPARE{n}_EN
    0=Normal operation; 1=Use the state of TSM_SPARE{n}_EN_OVRD to override the signal "tsm_spare{n}_en"
